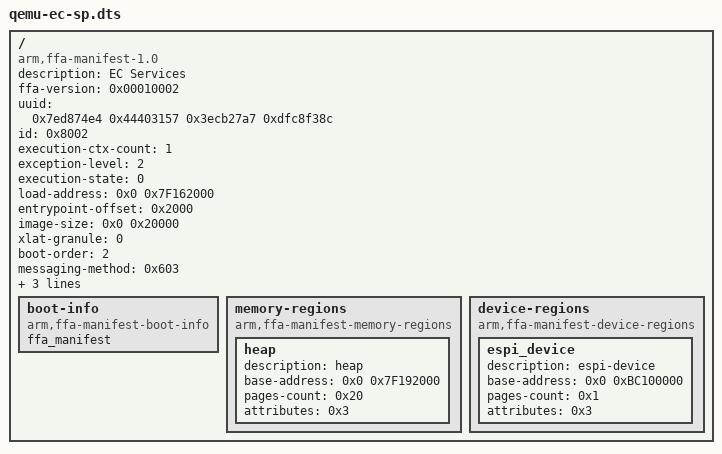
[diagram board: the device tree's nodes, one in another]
/*
 * Copyright (c) 2020-21, ARM Limited and Contributors. All rights reserved.
 *
 * SPDX-License-Identifier: BSD-3-Clause
 */

/dts-v1/;

/ {
	/*
	 * EC Service partition handles the following UUID'S
	 * INTER-PARTITION      e474d87e-5731-4044-a727-cb3e8cf3c8df
	 * EC_SVC_MANAGEMENT 	330c1273-fde5-4757-9819-5b6539037502
	 * EC_SVC_POWER 		7157addf-2fbe-4c63-ae95-efac16e3b01c
	 * EC_SVC_BATTERY 		25cb5207-ac36-427d-aaef-3aa78877d27e
	 * EC_SVC_THERMAL		31f56da7-593c-4d72-a4b3-8fc7171ac073
	 */

	compatible = "arm,ffa-manifest-1.0";

	description = "EC Services";
	ffa-version = <0x00010002>; /* 31:16 - Major, 15:0 - Minor */
	uuid = <0x7ed874e4 0x44403157 0x3ecb27a7 0xdfc8f38c>;
	id = <0x8002>;
	execution-ctx-count = <1>;
	exception-level = <2>; /* SEL1*/
	execution-state = <0>; /* AArch64*/
	load-address = <0x0 0x7F162000>;
	entrypoint-offset = <0x2000>;
	image-size = <0x0 0x20000>;
	xlat-granule = <0>; /* 4KiB */
	boot-order = <2>;
	messaging-method = <0x603>; /* Direct request/response req2/rsp2 supported. */
	ns-interrupts-action = <0>; /* Non-secure interrupt is signaled */
	notification-support; /* Support receipt of notifications. */
	gp-register-num = <0>;

	boot-info {
		compatible = "arm,ffa-manifest-boot-info";
		ffa_manifest;
	};

	memory-regions {
		compatible = "arm,ffa-manifest-memory-regions";

      	  // Heap used by RUST code in SP
	  heap {
	  	description = "heap";
		base-address = <0x0 0x7F192000>;
		pages-count = <0x20>; /* 128KB of Heap space */
		attributes = <0x3>;
	  };
       };

       device-regions {
         compatible = "arm,ffa-manifest-device-regions";

         // Access to eSPI
         espi_device {
           description = "espi-device";
           base-address = <0x0 0xBC100000>;
           pages-count = <0x1>;
           attributes = <0x3>;
         };

       };

};
